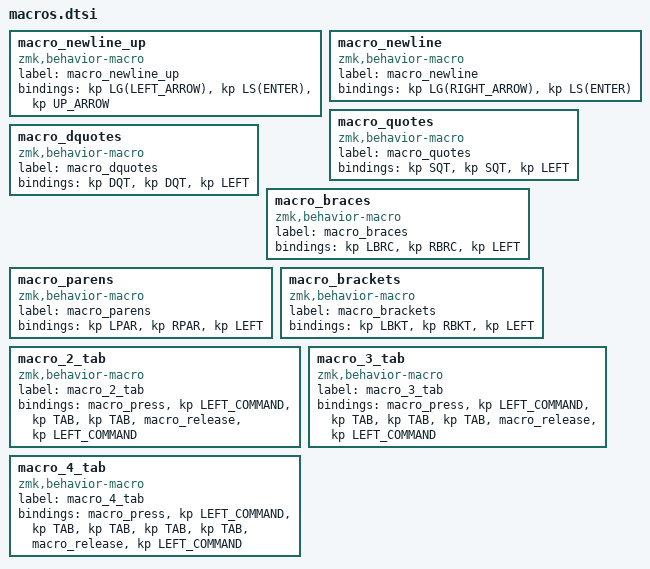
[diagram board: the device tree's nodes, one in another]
macro_newline_up: macro_newline_up{
compatible = "zmk,behavior-macro";
label = "macro_newline_up";
#binding-cells = <0>;
bindings = <&kp LG(LEFT_ARROW)>, <&kp LS(ENTER)>, <&kp UP_ARROW>;
};
macro_newline: macro_newline{
compatible = "zmk,behavior-macro";
label = "macro_newline";
#binding-cells = <0>;
bindings = <&kp LG(RIGHT_ARROW)>, <&kp LS(ENTER)>;
};
macro_quotes: macro_quotes{
compatible = "zmk,behavior-macro";
label = "macro_quotes";
#binding-cells = <0>;
bindings = <&kp SQT>, <&kp SQT>, <&kp LEFT>;
};
macro_dquotes: macro_dquotes{
compatible = "zmk,behavior-macro";
label = "macro_dquotes";
#binding-cells = <0>;
bindings = <&kp DQT>, <&kp DQT>, <&kp LEFT>;
};
macro_braces: macro_braces{
compatible = "zmk,behavior-macro";
label = "macro_braces";
#binding-cells = <0>;
bindings = <&kp LBRC>, <&kp RBRC>, <&kp LEFT>;
};
macro_parens: macro_parens{
compatible = "zmk,behavior-macro";
label = "macro_parens";
#binding-cells = <0>;
bindings = <&kp LPAR>, <&kp RPAR>, <&kp LEFT>;
};
macro_brackets: macro_brackets{
compatible = "zmk,behavior-macro";
label = "macro_brackets";
#binding-cells = <0>;
bindings = <&kp LBKT>, <&kp RBKT>, <&kp LEFT>;
};
macro_2_tab: macro_2_tab{
compatible = "zmk,behavior-macro";
label = "macro_2_tab";
#binding-cells = <0>;
bindings = <&macro_press &kp LEFT_COMMAND>, <&kp TAB>, <&kp TAB>, <&macro_release &kp LEFT_COMMAND>;
};
macro_3_tab: macro_3_tab{
compatible = "zmk,behavior-macro";
label = "macro_3_tab";
#binding-cells = <0>;
bindings = <&macro_press &kp LEFT_COMMAND>, <&kp TAB>, <&kp TAB>, <&kp TAB>, <&macro_release &kp LEFT_COMMAND>;
};
macro_4_tab: macro_4_tab{
compatible = "zmk,behavior-macro";
label = "macro_4_tab";
#binding-cells = <0>;
bindings = <&macro_press &kp LEFT_COMMAND>, <&kp TAB>, <&kp TAB>, <&kp TAB>, <&kp TAB>, <&macro_release &kp LEFT_COMMAND>;
};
